AUTOSAR XML (schema 4-0-3)
standard types defined: Boolean, UInt16, UInt32
package /AUTOSAR_Platform/DataConstrs
  range DC_Boolean: raw 0..1
  range DC_UInt16: raw 0..65535
package /PATAC/MSM/ComponentTypes
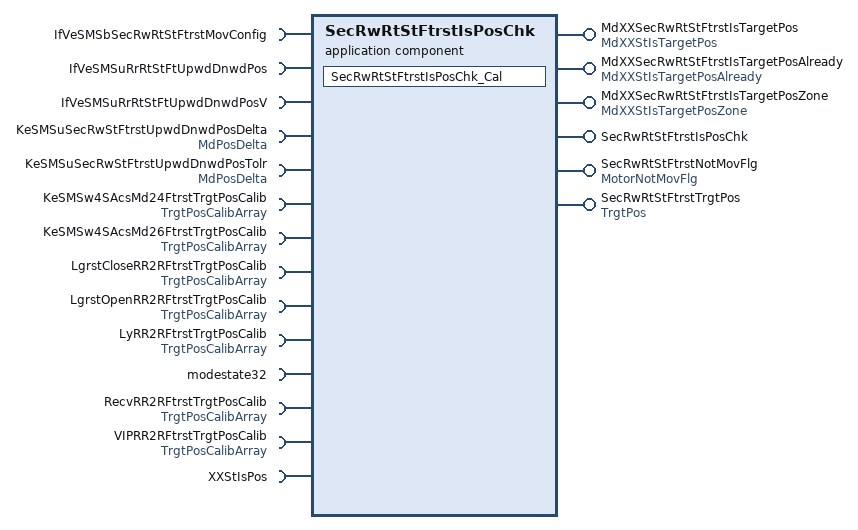
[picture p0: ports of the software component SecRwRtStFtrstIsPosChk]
  application sw component type SecRwRtStFtrstIsPosChk
    6 x provide port:
      MdXXSecRwRtStFtrstIsTargetPos: nonqueued-sender-com-spec=data-element=MdXXStIsTargetPos/Val, provided-interface=MdXXStIsTargetPos
      MdXXSecRwRtStFtrstIsTargetPosAlready: nonqueued-sender-com-spec=data-element=MdXXStIsTargetPosAlready/Val, provided-interface=MdXXStIsTargetPosAlready
      MdXXSecRwRtStFtrstIsTargetPosZone: nonqueued-sender-com-spec=data-element=MdXXStIsTargetPosZone/Val, provided-interface=MdXXStIsTargetPosZone
      SecRwRtStFtrstIsPosChk: server-com-spec{operation=Cal, queue-length=1}, provided-interface=SecRwRtStFtrstIsPosChk
      SecRwRtStFtrstNotMovFlg: nonqueued-sender-com-spec{data-element=MotorNotMovFlg/Val, init-value=0}, provided-interface=MotorNotMovFlg
      SecRwRtStFtrstTrgtPos: nonqueued-sender-com-spec{data-element=TrgtPos/Val, init-value=4095}, provided-interface=TrgtPos
    14 x require port:
      IfVeSMSbSecRwRtStFtrstMovConfig: nonqueued-receiver-com-spec{data-element=IfVeSMSbSecRwRtStFtrstMovConfig/Val, filter=data-filter-type=ALWAYS, init-value=0}, required-interface=IfVeSMSbSecRwRtStFtrstMovConfig
      IfVeSMSuRrRtStFtUpwdDnwdPos: nonqueued-receiver-com-spec{data-element=IfVeSMSuRrRtStFtUpwdDnwdPos/Val, filter=data-filter-type=ALWAYS, init-value=0}, required-interface=IfVeSMSuRrRtStFtUpwdDnwdPos
      IfVeSMSuRrRtStFtUpwdDnwdPosV: nonqueued-receiver-com-spec{data-element=IfVeSMSuRrRtStFtUpwdDnwdPosV/Val, filter=data-filter-type=ALWAYS, init-value=0}, required-interface=IfVeSMSuRrRtStFtUpwdDnwdPosV
      KeSMSuSecRwStFtrstUpwdDnwdPosDelta: parameter-require-com-spec{init-value=150, parameter=Val}, required-interface=MdPosDelta
      KeSMSuSecRwStFtrstUpwdDnwdPosTolr: parameter-require-com-spec{init-value=150, parameter=Val}, required-interface=MdPosDelta
      KeSMSw4SAcsMd24FtrstTrgtPosCalib: nonqueued-receiver-com-spec{data-element=TrgtPosArray, filter=data-filter-type=ALWAYS, init-value=[4095, 4095, 4095]}, required-interface=TrgtPosCalibArray
      KeSMSw4SAcsMd26FtrstTrgtPosCalib: nonqueued-receiver-com-spec{data-element=TrgtPosArray, filter=data-filter-type=ALWAYS, init-value=[4095, 4095, 4095]}, required-interface=TrgtPosCalibArray
      LgrstCloseRR2RFtrstTrgtPosCalib: nonqueued-receiver-com-spec{data-element=TrgtPosArray, filter=data-filter-type=ALWAYS, init-value=[4095, 4095, 4095]}, required-interface=TrgtPosCalibArray
      LgrstOpenRR2RFtrstTrgtPosCalib: nonqueued-receiver-com-spec{data-element=TrgtPosArray, filter=data-filter-type=ALWAYS, init-value=[4095, 4095, 4095]}, required-interface=TrgtPosCalibArray
      LyRR2RFtrstTrgtPosCalib: nonqueued-receiver-com-spec{data-element=TrgtPosArray, filter=data-filter-type=ALWAYS, init-value=[4095, 4095, 4095]}, required-interface=TrgtPosCalibArray
      modestate32: nonqueued-receiver-com-spec{data-element=modestate32/Val, filter=data-filter-type=ALWAYS, init-value=0}, required-interface=modestate32
      RecvRR2RFtrstTrgtPosCalib: nonqueued-receiver-com-spec{data-element=TrgtPosArray, filter=data-filter-type=ALWAYS, init-value=[4095, 4095, 4095]}, required-interface=TrgtPosCalibArray
      VIPRR2RFtrstTrgtPosCalib: nonqueued-receiver-com-spec{data-element=TrgtPosArray, filter=data-filter-type=ALWAYS, init-value=[4095, 4095, 4095]}, required-interface=TrgtPosCalibArray
      XXStIsPos: client-com-spec=Get, required-interface=XXStIsPos
    behavior SecRwRtStFtrstIsPosChk_InternalBehavior
      operation invoked event OIT_SecRwRtStFtrstIsPosChk_Cal_SecRwRtStFtrstIsPosChk_Cal: start-on-event=SecRwRtStFtrstIsPosChk_Cal, operation=SecRwRtStFtrstIsPosChk.Cal
      runnable SecRwRtStFtrstIsPosChk_Cal
        data-receive-point-by-arguments:
          11 x access:
            REC_IfVeSMSbSecRwRtStFtrstMovConfig_Val: accessed-variable=IfVeSMSbSecRwRtStFtrstMovConfig.Val
            REC_IfVeSMSuRrRtStFtUpwdDnwdPos_Val: accessed-variable=IfVeSMSuRrRtStFtUpwdDnwdPos.Val
            REC_IfVeSMSuRrRtStFtUpwdDnwdPosV_Val: accessed-variable=IfVeSMSuRrRtStFtUpwdDnwdPosV.Val
            REC_KeSMSw4SAcsMd24FtrstTrgtPosCalib_TrgtPosArray: accessed-variable=KeSMSw4SAcsMd24FtrstTrgtPosCalib.TrgtPosArray
            REC_KeSMSw4SAcsMd26FtrstTrgtPosCalib_TrgtPosArray: accessed-variable=KeSMSw4SAcsMd26FtrstTrgtPosCalib.TrgtPosArray
            REC_LgrstCloseRR2RFtrstTrgtPosCalib_TrgtPosArray: accessed-variable=LgrstCloseRR2RFtrstTrgtPosCalib.TrgtPosArray
            REC_LgrstOpenRR2RFtrstTrgtPosCalib_TrgtPosArray: accessed-variable=LgrstOpenRR2RFtrstTrgtPosCalib.TrgtPosArray
            REC_LyRR2RFtrstTrgtPosCalib_TrgtPosArray: accessed-variable=LyRR2RFtrstTrgtPosCalib.TrgtPosArray
            REC_modestate32_Val: accessed-variable=modestate32.Val
            REC_RecvRR2RFtrstTrgtPosCalib_TrgtPosArray: accessed-variable=RecvRR2RFtrstTrgtPosCalib.TrgtPosArray
            REC_VIPRR2RFtrstTrgtPosCalib_TrgtPosArray: accessed-variable=VIPRR2RFtrstTrgtPosCalib.TrgtPosArray
        data-send-points:
          5 x access:
            SEND_MdXXSecRwRtStFtrstIsTargetPos_Val: accessed-variable=MdXXSecRwRtStFtrstIsTargetPos.Val
            SEND_MdXXSecRwRtStFtrstIsTargetPosAlready_Val: accessed-variable=MdXXSecRwRtStFtrstIsTargetPosAlready.Val
            SEND_MdXXSecRwRtStFtrstIsTargetPosZone_Val: accessed-variable=MdXXSecRwRtStFtrstIsTargetPosZone.Val
            SEND_SecRwRtStFtrstNotMovFlg_Val: accessed-variable=SecRwRtStFtrstNotMovFlg.Val
            SEND_SecRwRtStFtrstTrgtPos_Val: accessed-variable=SecRwRtStFtrstTrgtPos.Val
        parameter access PA_KeSMSuSecRwStFtrstUpwdDnwdPosDelta_Val: accessed-parameter=KeSMSuSecRwStFtrstUpwdDnwdPosDelta.Val
        parameter access PA_KeSMSuSecRwStFtrstUpwdDnwdPosTolr_Val: accessed-parameter=KeSMSuSecRwStFtrstUpwdDnwdPosTolr.Val
        sync call SC_XXStIsPos_Get: operation=XXStIsPos.Get, timeout=0
  swc implementation SecRwRtStFtrstIsPosChk_Implementation: behavior=SecRwRtStFtrstIsPosChk_InternalBehavior
    code-descriptors:
      code Default: artifact-descriptors=autosar-engineering-object={short-label=Default, category=SWSRC}
package /PATAC/MSM/ModeAdjust/CalPortInterface
  parameter interface MdPosDelta
    parameter data prototype Val: sw-calibration-access=READ-WRITE, type=UInt16
package /PATAC/MSM/ModeAdjust/DataType
  impl type TrgtPosCalibArray: category=ARRAY, sw-calibration-access=READ-ONLY, type-emitter=RTE  # 0:pos 1:max 2:min
    element Element: array-size=3, array-size-semantics=FIXED-SIZE, implementation-data-type=UInt16, invalid-value=0
package /PATAC/MSM/ModeAdjust/PortInterface
  client server interface SecRwRtStFtrstIsPosChk
    operation Cal
  client server interface XXStIsPos
    operation Get
      8 x arg, all with server-argument-impl-policy=USE-ARGUMENT-TYPE:
        PosV: type=DataTypes/Boolean, direction=IN
        Pos: type=UInt16, direction=IN
        CalibArray: type=TrgtPosCalibArray, direction=IN
        Delta: type=UInt16, direction=IN
        Tolr: type=UInt16, direction=IN
        IsPos: type=DataTypes/Boolean, direction=OUT
        IsPosZone: type=DataTypes/Boolean, direction=OUT
        IsPosAlready: type=DataTypes/Boolean, direction=OUT
  7 x sender receiver interface:
    IfVeSMSbSecRwRtStFtrstMovConfig: invalidation-policy{data-element=IfVeSMSbSecRwRtStFtrstMovConfig/Val, handle-invalid=DONT-INVALIDATE}
      data Val: type=Implementation/Boolean
    MdXXStIsTargetPos: invalidation-policy{data-element=MdXXStIsTargetPos/Val, handle-invalid=DONT-INVALIDATE}
      data Val: type=UInt32
    MdXXStIsTargetPosAlready: invalidation-policy{data-element=MdXXStIsTargetPosAlready/Val, handle-invalid=DONT-INVALIDATE}
      data Val: type=UInt32
    MdXXStIsTargetPosZone: invalidation-policy{data-element=MdXXStIsTargetPosZone/Val, handle-invalid=DONT-INVALIDATE}
      data Val: type=UInt32
    modestate32: invalidation-policy{data-element=modestate32/Val, handle-invalid=DONT-INVALIDATE}
      data Val: type=UInt32
    MotorNotMovFlg: invalidation-policy{data-element=MotorNotMovFlg/Val, handle-invalid=DONT-INVALIDATE}
      data Val: type=Implementation/Boolean
    TrgtPosCalibArray: invalidation-policy{data-element=TrgtPosArray, handle-invalid=DONT-INVALIDATE}
      data TrgtPosArray: type=TrgtPosCalibArray  # 0:Pos 1:Max 2:Min
package /PATAC/MSM/PortInterfaces
  sender receiver interface IfVeSMSuRrRtStFtUpwdDnwdPos: invalidation-policy{data-element=IfVeSMSuRrRtStFtUpwdDnwdPos/Val, handle-invalid=DONT-INVALIDATE}
    data Val: type=UInt16
  sender receiver interface IfVeSMSuRrRtStFtUpwdDnwdPosV: invalidation-policy{data-element=IfVeSMSuRrRtStFtUpwdDnwdPosV/Val, handle-invalid=DONT-INVALIDATE}
    data Val: type=Implementation/Boolean
  sender receiver interface TrgtPos: invalidation-policy{data-element=TrgtPos/Val, handle-invalid=DONT-INVALIDATE}
    data Val: type=UInt16
